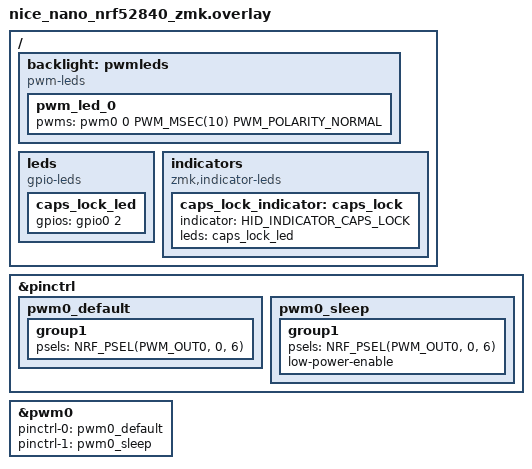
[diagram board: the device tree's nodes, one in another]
#include <dt-bindings/zmk/hid_indicators.h>

/ {
    backlight: pwmleds {
        compatible = "pwm-leds";
        status = "okay";
        pwm_led_0: pwm_led_0 {
            pwms = <&pwm0 0 PWM_MSEC(10) PWM_POLARITY_NORMAL>;
        };
    };

    leds {
        compatible = "gpio-leds";
        caps_lock_led: caps_lock_led {
            gpios = <&gpio0 2 GPIO_ACTIVE_HIGH>;  /* P0.02 */
        };
    };

    indicators {
        compatible = "zmk,indicator-leds";
        caps_lock_indicator: caps_lock {
            indicator = <HID_INDICATOR_CAPS_LOCK>;
            leds = <&caps_lock_led>;
        };
    };
};

&pinctrl {
    pwm0_default: pwm0_default {
        group1 {
            psels = <NRF_PSEL(PWM_OUT0, 0, 6)>;
        };
    };

    pwm0_sleep: pwm0_sleep {
        group1 {
            psels = <NRF_PSEL(PWM_OUT0, 0, 6)>;
            low-power-enable;
        };
    };
};

&pwm0 {
    status = "okay";
    pinctrl-0 = <&pwm0_default>;
    pinctrl-1 = <&pwm0_sleep>;
    pinctrl-names = "default", "sleep";
};
